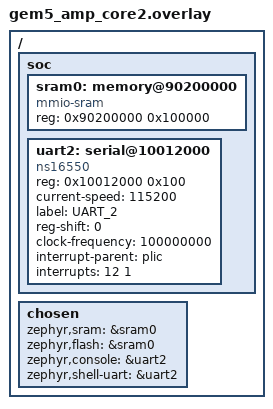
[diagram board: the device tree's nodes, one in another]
/ {
    soc {
        sram0: memory@90200000 {
            compatible = "mmio-sram";
            reg = <0x90200000 0x100000>;
        };
        
        uart2: serial@10012000 {
            compatible = "ns16550";
            reg = <0x10012000 0x100>;
            status = "okay";
            current-speed = <115200>;
            label = "UART_2";
            reg-shift = <0>;
            clock-frequency = <100000000>;
            interrupt-parent = <&plic>;
            interrupts = <12 1>;
        };
    };

    chosen {
        zephyr,sram = &sram0;
        zephyr,flash = &sram0;
        zephyr,console = &uart2;
        zephyr,shell-uart = &uart2;
    };
};

